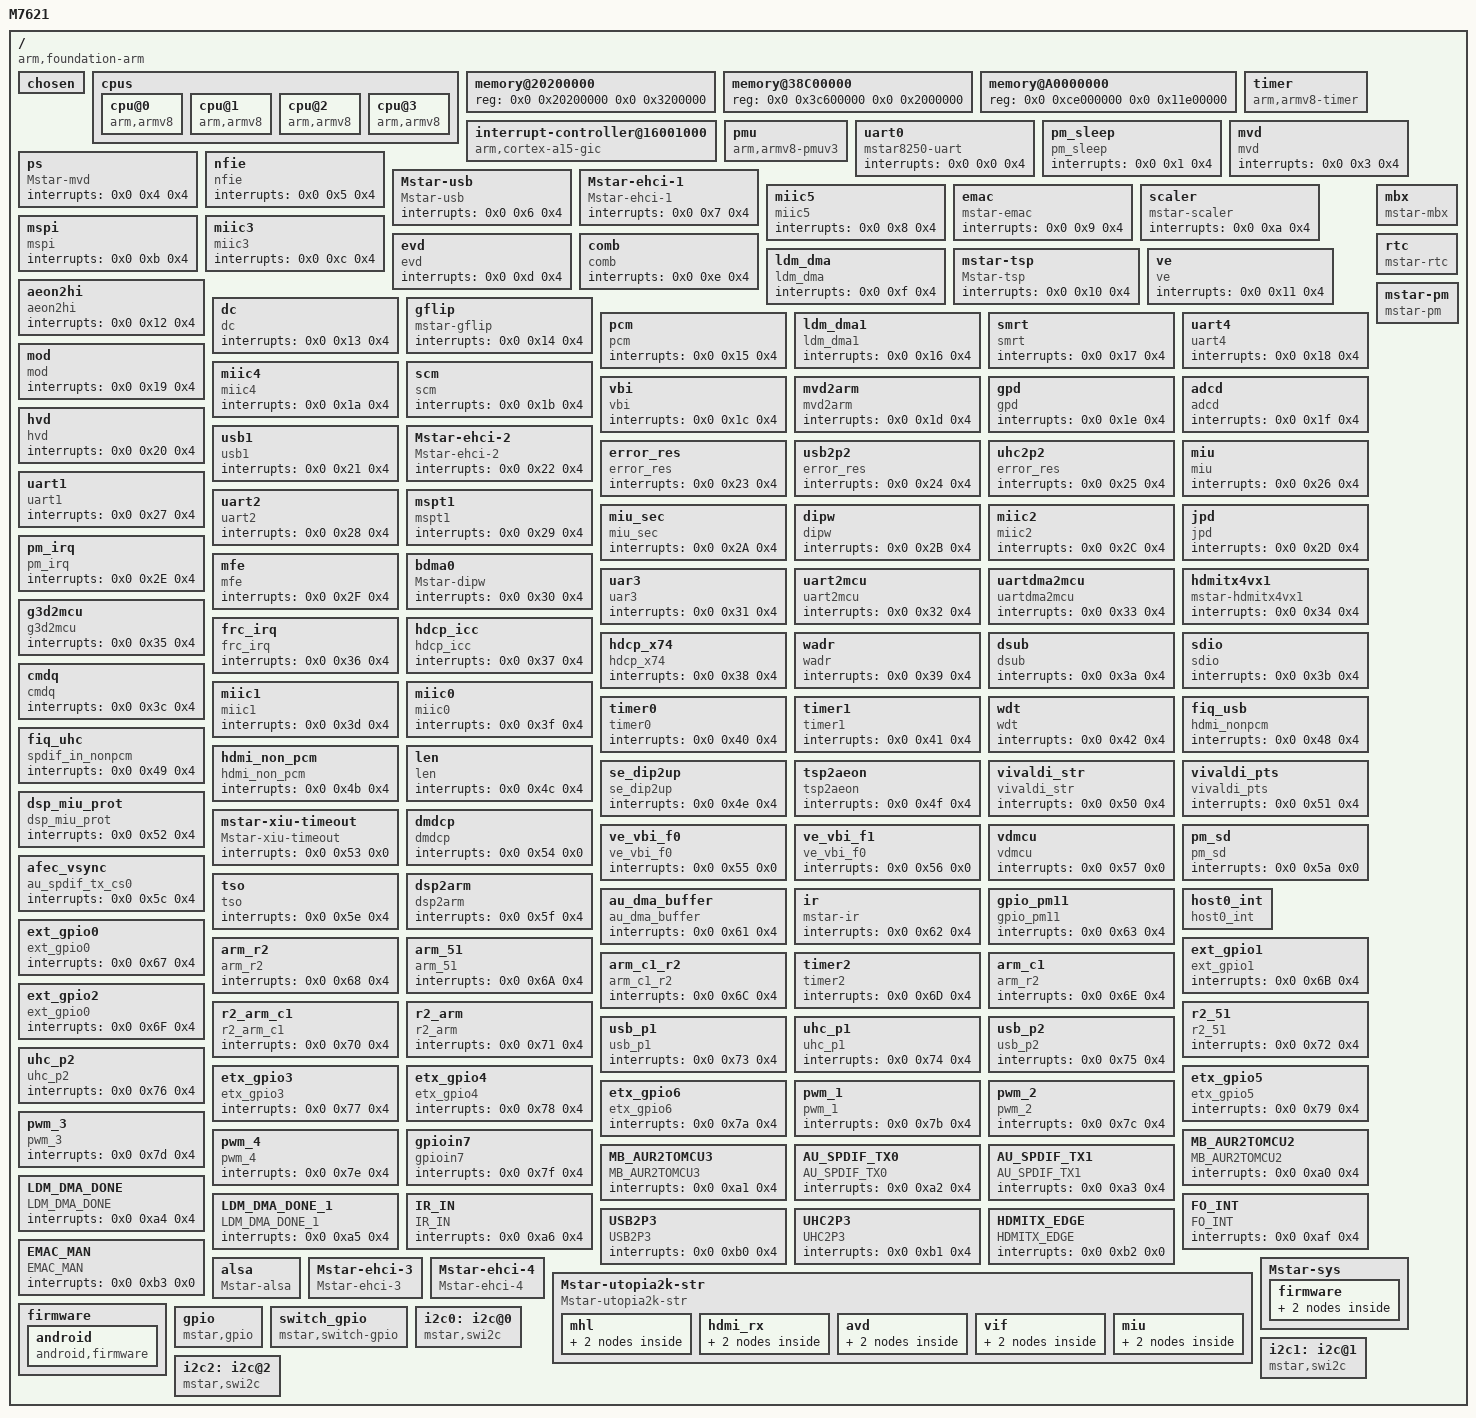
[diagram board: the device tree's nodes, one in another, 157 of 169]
/dts-v1/;

/ {
	model = "M7621";
	compatible = "arm,foundation-arm", "arm,m7621";
	interrupt-parent = <0x1>;
	#address-cells = <0x2>;
	#size-cells = <0x2>;

	chosen {
		bootargs = "root=/dev/mmcblk0p4 rootfstype=ext4 rw rootwait init=/sbin/init ip=dhcp console=ttyS0,115200 LX_MEM=0x3200000 LX_MEM2=0x3BC00000,0x2A00000 LX_MEM3=0xCE000000,0x11E00000";
	};

	cpus {
		#address-cells = <0x1>;
		#size-cells = <0x0>;

		cpu@0 {
			device_type = "cpu";
			compatible = "arm,armv8";
			reg = <0>;
			enable-method = "mstar-spin-table";
			cpu-release-addr = <0x100510>;
		};

		cpu@1 {
			device_type = "cpu";
			compatible = "arm,armv8";
			reg = <1>;
			enable-method = "mstar-spin-table";
			cpu-release-addr = <0x100510>;
		};
		cpu@2 {
			device_type = "cpu";
			compatible = "arm,armv8";
			reg = <2>;
			enable-method = "mstar-spin-table";
			cpu-release-addr = <0x100510>;
		};

		cpu@3 {
			device_type = "cpu";
			compatible = "arm,armv8";
			reg = <3>;
			enable-method = "mstar-spin-table";
			cpu-release-addr = <0x100510>;
		};

	};

	memory@20200000 {
		device_type = "memory";
		reg = <0x0 0x20200000 0x0 0x3200000>;
	};

	memory@38C00000 {
		device_type = "memory";
		reg = <0x0 0x3c600000 0x0 0x2000000>;
	};

	memory@A0000000 {
		device_type = "memory";
		reg = <0x0 0xce000000 0x0 0x11e00000>;
	};

	interrupt-controller@16001000 {
		compatible = "arm,cortex-a15-gic", "arm,cortex-a9-gic";
		#interrupt-cells = <0x3>;
		#address-cells = <0x0>;
		interrupt-controller;
		reg = <0x0 0x16001000 0x0 0x1000 0x0 0x16002000 0x0 0x4000>;
		interrupts = <0x1 0x9 0xf04>;
		linux,phandle = <0x1>;
		phandle = <0x1>;
	};

	timer {
		compatible = "arm,armv8-timer";
		interrupts =	<0x1 0xd 0xff01>,
				<0x1 0xe 0xff01>,
				<0x1 0xb 0xff01>,
				<0x1 0xa 0xff01>;
		clock-frequency = <0xb71b00>;
	};

	pmu {
		compatible = "arm,armv8-pmuv3";
		interrupts = <0x0 0x8a 0x4 0x0 0x8c 0x4 0x0 0x8e 0x4 0x0 0x90 0x4>;
	};

	uart0 {
		compatible = "mstar8250-uart";
		interrupts = <0x0 0x0 0x4>;
	};

	pm_sleep {
		compatible = "pm_sleep";
		interrupts = <0x0 0x1 0x4>;
	};

	mvd {
		compatible = "mvd";
		interrupts = <0x0 0x3 0x4>;
	};

	ps {
		compatible = "Mstar-mvd";
		interrupts = <0x0 0x4 0x4>;
	};

	nfie {
		compatible = "nfie";
		interrupts = <0x0 0x5 0x4>;
	};

	Mstar-usb {
		compatible = "Mstar-usb";
		interrupts = <0x0 0x6 0x4>;
	};

	Mstar-ehci-1 {
		compatible = "Mstar-ehci-1";
		interrupts = <0x0 0x7 0x4>;
	};

	miic5 {
		compatible = "miic5";
		interrupts = <0x0 0x8 0x4>;
	};

	emac {
		compatible = "mstar-emac";
		interrupts = <0x0 0x9 0x4>;
	};

	scaler {
		compatible = "mstar-scaler";
		interrupts = <0x0 0xa 0x4>;
	};

	mspi {
		compatible = "mspi";
		interrupts = <0x0 0xb 0x4>;
	};

	miic3 {
		compatible = "miic3";
		interrupts = <0x0 0xc 0x4>;
	};

	evd   {
		compatible = "evd";
		interrupts = <0x0 0xd 0x4>;
	};

	comb {
		compatible = "comb";
		interrupts = <0x0 0xe 0x4>;
	};

	ldm_dma {
		compatible = "ldm_dma";
		interrupts = <0x0 0xf 0x4>;
	};

	mstar-tsp {
		compatible = "Mstar-tsp";
		interrupts = <0x0 0x10 0x4>;
	};

	ve {
		compatible = "ve";
		interrupts = <0x0 0x11 0x4>;
	};

	aeon2hi {
		compatible = "aeon2hi";
		interrupts = <0x0 0x12 0x4>;
	};

	dc {
		compatible = "dc";
		interrupts = <0x0 0x13 0x4>;
	};

	gflip {
		compatible = "mstar-gflip";
		interrupts = <0x0 0x14 0x4>;
	};

	pcm {
		compatible = "pcm";
		interrupts = <0x0 0x15 0x4>;
	};

	ldm_dma1 {
		compatible = "ldm_dma1";
		interrupts = <0x0 0x16 0x4>;
	};

	smrt {
		compatible = "smrt";
		interrupts = <0x0 0x17 0x4>;
	};

	uart4{
		compatible = "uart4";
		interrupts = <0x0 0x18 0x4>;
	};

	mod {
		compatible = "mod";
		interrupts = <0x0 0x19 0x4>;
	};

	miic4 {
		compatible = "miic4";
		interrupts = <0x0 0x1a 0x4>;
	};

	scm {
		compatible = "scm";
		interrupts = <0x0 0x1b 0x4>;
	};

	vbi {
		compatible = "vbi";
		interrupts = <0x0 0x1c 0x4>;
	};

	mvd2arm {
		compatible = "mvd2arm";
		interrupts = <0x0 0x1d 0x4>;
	};

	gpd {
		compatible = "gpd";
		interrupts = <0x0 0x1e 0x4>;
	};

	adcd {
		compatible = "adcd";
		interrupts = <0x0 0x1f 0x4>;
	};

	hvd {
		compatible = "hvd";
		interrupts = <0x0 0x20 0x4>;
	};

	usb1 {
		compatible = "usb1";
		interrupts = <0x0 0x21 0x4>;
	};

	Mstar-ehci-2 {
		compatible = "Mstar-ehci-2";
		interrupts = <0x0 0x22 0x4>;
	};

	error_res {
		compatible = "error_res";
		interrupts = <0x0 0x23 0x4>;
	};

	usb2p2 {
		compatible = "error_res";
		interrupts = <0x0 0x24 0x4>;
	};

	uhc2p2 {
		compatible = "error_res";
		interrupts = <0x0 0x25 0x4>;
	};

	miu {
		compatible = "miu";
		interrupts = <0x0 0x26 0x4>;
	};

	uart1 {
		compatible = "uart1";
		interrupts = <0x0 0x27 0x4>;
	};

	uart2 {
		compatible = "uart2";
		interrupts = <0x0 0x28 0x4>;
	};

	mspt1 {
		compatible = "mspt1";
		interrupts = <0x0 0x29 0x4>;
	};

	miu_sec {
		compatible = "miu_sec";
		interrupts = <0x0 0x2A 0x4>;
	};

	dipw {
		compatible = "dipw";
		interrupts = <0x0 0x2B 0x4>;
	};

	miic2 {
		compatible = "miic2";
		interrupts = <0x0 0x2C 0x4>;
	};

	jpd {
		compatible = "jpd";
		interrupts = <0x0 0x2D 0x4>;
	};

	pm_irq {
		compatible = "pm_irq";
		interrupts = <0x0 0x2E 0x4>;
	};

	mfe {
		compatible = "mfe";
		interrupts = <0x0 0x2F 0x4>;
	};

	bdma0 {
		compatible = "Mstar-dipw";
		interrupts = <0x0 0x30 0x4>;
	};

	uar3 {
		compatible = "uar3";
		interrupts = <0x0 0x31 0x4>;
	};

	uart2mcu {
		compatible = "uart2mcu";
		interrupts = <0x0 0x32 0x4>;
	};

	uartdma2mcu {
		compatible = "uartdma2mcu";
		interrupts = <0x0 0x33 0x4>;
	};

	hdmitx4vx1 {
		compatible = "mstar-hdmitx4vx1";
		interrupts = <0x0 0x34 0x4>;
	};

	g3d2mcu {
		compatible = "g3d2mcu";
		interrupts = <0x0 0x35 0x4>;
	};

	frc_irq{
		compatible = "frc_irq";
		interrupts = <0x0 0x36 0x4>;
	};

	hdcp_icc {
		compatible = "hdcp_icc";
		interrupts = <0x0 0x37 0x4>;
	};

	hdcp_x74 {
		compatible = "hdcp_x74 ";
		interrupts = <0x0 0x38 0x4>;
	};

	wadr {
		compatible = "wadr";
		interrupts = <0x0 0x39 0x4>;
	};

	dsub {
		compatible = "dsub";
		interrupts = <0x0 0x3a 0x4>;
	};

	sdio {
		compatible = "sdio";
		interrupts = <0x0 0x3b 0x4>;
	};

	cmdq {
		compatible = "cmdq ";
		interrupts = <0x0 0x3c 0x4>;
	};

	miic1 {
		compatible = "miic1";
		interrupts = <0x0 0x3d 0x4>;
	};

	miic0 {
		compatible = "miic0";
		interrupts = <0x0 0x3f 0x4>;
	};

	timer0{
		compatible = "timer0";
		interrupts = <0x0 0x40 0x4>;
	};

	timer1{
		compatible = "timer1";
		interrupts = <0x0 0x41 0x4>;
	};

	wdt {
		compatible = "wdt";
		interrupts = <0x0 0x42 0x4>;
	};

	mbx {
		compatible = "mstar-mbx";
		interrupts = <0x0 0x44 0x4 0x0 0x45 0x4  0x0 0x46 0x4  0x0 0x47 0x4>;
	};

	fiq_usb {
		compatible = "hdmi_nonpcm";
		interrupts = <0x0 0x48 0x4>;
	};

	fiq_uhc {
		compatible = "spdif_in_nonpcm";
		interrupts = <0x0 0x49 0x4>;
	};

	hdmi_non_pcm {
		compatible = "hdmi_non_pcm";
		interrupts = <0x0 0x4b 0x4>;
	};

	len {
		compatible = "len";
		interrupts = <0x0 0x4c 0x4>;
	};

	se_dip2up {
		compatible = "se_dip2up";
		interrupts = <0x0 0x4e 0x4>;
	};

	tsp2aeon {
		compatible = "tsp2aeon";
		interrupts = <0x0 0x4f 0x4>;
	};

	vivaldi_str {
		compatible = "vivaldi_str";
		interrupts = <0x0 0x50 0x4>;
	};

	vivaldi_pts {
		compatible = "vivaldi_pts";
		interrupts = <0x0 0x51 0x4>;
	};

	dsp_miu_prot {
		compatible = "dsp_miu_prot";
		interrupts = <0x0 0x52 0x4>;
	};

	mstar-xiu-timeout {
		compatible = "Mstar-xiu-timeout";
		interrupts = <0x0 0x53 0x0>;
	};

    dmdcp {
		compatible = "dmdcp";
		interrupts = <0x0 0x54 0x0>;
	};

    ve_vbi_f0 {
		compatible = "ve_vbi_f0";
		interrupts = <0x0 0x55 0x0>;
	};

    ve_vbi_f1 {
		compatible = "ve_vbi_f0";
		interrupts = <0x0 0x56 0x0>;
	};

    vdmcu {
		compatible = "vdmcu";
		interrupts = <0x0 0x57 0x0>;
	};

    pm_sd {
		compatible = "pm_sd";
		interrupts = <0x0 0x5a 0x0>;
	};

	afec_vsync {
		compatible = "au_spdif_tx_cs0";
		interrupts = <0x0 0x5c 0x4>;
	};

	tso {
		compatible = "tso";
		interrupts = <0x0 0x5e 0x4>;
	};

	dsp2arm {
		compatible = "dsp2arm";
		interrupts = <0x0 0x5f 0x4>;
	};

	au_dma_buffer {
		compatible = "au_dma_buffer";
		interrupts = <0x0 0x61 0x4>;
	};

	ir {
		compatible = "mstar-ir";
		interrupts = <0x0 0x62 0x4>;
	};

	gpio_pm11 {
		compatible = "gpio_pm11";
		interrupts = <0x0 0x63 0x4>;
	};

	host0_int {
		compatible = "host0_int";
		interrupts = <0x0 0x64 0x4  0x0 0x65 0x4  0x0 0x66 0x4>;
	};

	ext_gpio0 {
		compatible = "ext_gpio0";
		interrupts = <0x0 0x67 0x4>;
	};

	arm_r2 {
		compatible = "arm_r2";
		interrupts = <0x0 0x68 0x4>;
	};

	arm_51 {
		compatible = "arm_51";
		interrupts = <0x0 0x6A 0x4>;
	};

	ext_gpio1 {
		compatible = "ext_gpio1";
		interrupts = <0x0 0x6B 0x4>;
	};

	arm_c1_r2 {
		compatible = "arm_c1_r2";
		interrupts = <0x0 0x6C 0x4>;
	};

	timer2 {
		compatible = "timer2";
		interrupts = <0x0 0x6D 0x4>;
	};

	arm_c1 {
		compatible = "arm_r2";
		interrupts = <0x0 0x6E 0x4>;
	};

	ext_gpio2 {
		compatible = "ext_gpio0";
		interrupts = <0x0 0x6F 0x4>;
	};

	r2_arm_c1 {
		compatible = "r2_arm_c1";
		interrupts = <0x0 0x70 0x4>;
	};

	r2_arm {
		compatible = "r2_arm";
		interrupts = <0x0 0x71 0x4>;
	};

	r2_51 {
		compatible = "r2_51";
		interrupts = <0x0 0x72 0x4>;
	};

	usb_p1 {
		compatible = "usb_p1";
		interrupts = <0x0 0x73 0x4>;
	};

	uhc_p1 {
		compatible = "uhc_p1";
		interrupts = <0x0 0x74 0x4>;
	};

	usb_p2 {
		compatible = "usb_p2";
		interrupts = <0x0 0x75 0x4>;
	};

	uhc_p2 {
		compatible = "uhc_p2";
		interrupts = <0x0 0x76 0x4>;
	};

	etx_gpio3 {
		compatible = "etx_gpio3";
		interrupts = <0x0 0x77 0x4>;
	};

	etx_gpio4 {
		compatible = "etx_gpio4";
		interrupts = <0x0 0x78 0x4>;
	};
	etx_gpio5 {
		compatible = "etx_gpio5";
		interrupts = <0x0 0x79 0x4>;
	};

	etx_gpio6 {
		compatible = "etx_gpio6";
		interrupts = <0x0 0x7a 0x4>;
	};

	pwm_1 {
		compatible = "pwm_1";
		interrupts = <0x0 0x7b 0x4>;
	};

	pwm_2 {
		compatible = "pwm_2";
		interrupts = <0x0 0x7c 0x4>;
	};

	pwm_3 {
		compatible = "pwm_3";
		interrupts = <0x0 0x7d 0x4>;
	};

	pwm_4 {
		compatible = "pwm_4";
		interrupts = <0x0 0x7e 0x4>;
	};

	gpioin7 {
		compatible = "gpioin7";
		interrupts = <0x0 0x7f 0x4>;
	};

	MB_AUR2TOMCU2 {
		compatible = "MB_AUR2TOMCU2";
		interrupts = <0x0 0xa0 0x4>;
	};

	MB_AUR2TOMCU3 {
		compatible = "MB_AUR2TOMCU3";
		interrupts = <0x0 0xa1 0x4>;
	};

	AU_SPDIF_TX0 {
		compatible = "AU_SPDIF_TX0";
		interrupts = <0x0 0xa2 0x4>;
	};

	AU_SPDIF_TX1 {
		compatible = "AU_SPDIF_TX1";
		interrupts = <0x0 0xa3 0x4>;
	};

	LDM_DMA_DONE {
		compatible = "LDM_DMA_DONE";
		interrupts = <0x0 0xa4 0x4>;
	};

	LDM_DMA_DONE_1 {
		compatible = "LDM_DMA_DONE_1";
		interrupts = <0x0 0xa5 0x4>;
	};

	IR_IN {
		compatible = "IR_IN";
		interrupts = <0x0 0xa6 0x4>;
	};

    FO_INT{
		compatible = "FO_INT ";
		interrupts = <0x0 0xaf 0x4>;
	};

	USB2P3 {
		compatible = "USB2P3";
		interrupts = <0x0 0xb0 0x4>;
	};

    UHC2P3 {
		compatible = "UHC2P3";
		interrupts = <0x0 0xb1 0x4>;
	};

	HDMITX_EDGE {
		compatible = "HDMITX_EDGE";
		interrupts = <0x0 0xb2 0x0>;
	};

	EMAC_MAN  {
		compatible = "EMAC_MAN";
		interrupts = <0x0 0xb3 0x0>;
	};

	alsa {
		compatible = "Mstar-alsa";
	};

	rtc {
		compatible = "mstar-rtc";
	};

	mstar-pm {
		compatible = "mstar-pm";
	};

	Mstar-ehci-3 {
		compatible = "Mstar-ehci-3";
	};

	Mstar-ehci-4 {
		compatible = "Mstar-ehci-4";
	};

	Mstar-utopia2k-str {
		compatible = "Mstar-utopia2k-str";
		mhl {
		  resume {
		    stage0 {
		      pre-condition = "hdmi_rx";
		    };
		  };
		};
		hdmi_rx {
		  resume {
		    stage0 {
		      post-condition = "hdmi_rx";
		    };
		  };
		};
		avd {
		  resume {
		    stage0 {
		      pre-condition = "vif";
		    };
		  };
		};
		vif {
		  resume {
		    stage0 {
		      post-condition = "vif";
		    };
		  };
		};
        miu {
          resume {
            stage0 {
              post-condition = "miu";
            };
          };
        };
	};

        Mstar-sys {
                firmware {
                        audio {
                                path = "/vendor/lib/utopia/";
                        };
                        vdec {
                                path = "/vendor/lib/utopia/";
                        };
                };
        };

	firmware {

		android {
			compatible = "android,firmware";
			hardware ="m7621";
			revision ="1234";
			Serial   ="0000000000000000";
			Processor ="AArch64 Processor rev 3 (aarch64)";
			serialno ="123456789";
			mode ="123456789";
			baseband ="123456789";
			bootloader ="123456789";
		};
	};

    gpio: gpio{
        compatible = "mstar,gpio";
        gpio-controller;
        #gpio-cells = <1>;
        interrupt-controller;
        skip-save-status = <9 53>;
        #interrupt-cells = <2>; /* cell name GPIO_PAD, trigger-type*/
    };

	switch_gpio {
		compatible = "mstar,switch-gpio";
		switch-name = "h2w";
		switch-gpio = <999>;
		switch-inverse = <0>;
	};

	/* example of consume a gpio pin with mapped irq
	foo{
		interrupt-parent = <&gpio>;
		interrupts = <0 LEVEL_HIGH>;
	}
	*/
	i2c0: i2c@0 {
		compatible = "mstar,swi2c";
		bus-index = <0>;
		sda-gpio = <63>;
		scl-gpio = <62>;
		speed-khz = <100>;
		def-delay = <100>;
		retries = <5>;
		status = "okay";
		iic-mode = <0>;
		hw-port = <0>;
		pad-mux = <0>;
	};
	i2c1: i2c@1 {
		compatible = "mstar,swi2c";
		bus-index = <1>;
		sda-gpio = <161>;
		scl-gpio = <160>;
		speed-khz = <100>;
		def-delay = <100>;
		retries = <5>;
		status = "okay";
		iic-mode = <0>;
		hw-port = <0>;
		pad-mux = <0>;
	};
	i2c2: i2c@2 {
		compatible = "mstar,swi2c";
		bus-index = <2>;
		sda-gpio = <99>;
		scl-gpio = <98>;
		speed-khz = <100>;
		def-delay = <100>;
		retries = <5>;
		status = "okay";
		iic-mode = <0>;
		hw-port = <0>;
		pad-mux = <0>;
	};
};
